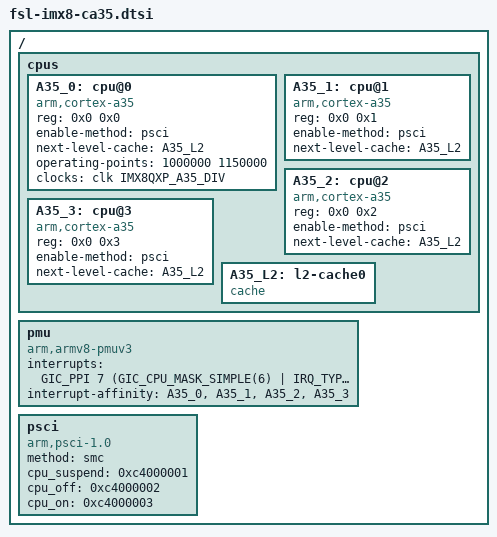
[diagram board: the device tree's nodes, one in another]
/*
 * Copyright (C) 2016 Freescale Semiconductor, Inc.
 * Copyright 2017 NXP
 *
 * This program is free software; you can redistribute it and/or
 * modify it under the terms of the GNU General Public License
 * as published by the Free Software Foundation; either version 2
 * of the License, or (at your option) any later version.
 *
 * This program is distributed in the hope that it will be useful,
 * but WITHOUT ANY WARRANTY; without even the implied warranty of
 * MERCHANTABILITY or FITNESS FOR A PARTICULAR PURPOSE.  See the
 * GNU General Public License for more details.
 */

#include <dt-bindings/clock/imx8qxp-clock.h>
#include <dt-bindings/interrupt-controller/arm-gic.h>

/{
	cpus {
		#address-cells = <2>;
		#size-cells = <0>;

		/* We have 1 clusters having 4 Cortex-A35 cores */
		A35_0: cpu@0 {
			device_type = "cpu";
			compatible = "arm,cortex-a35";
			reg = <0x0 0x0>;
			enable-method = "psci";
			next-level-cache = <&A35_L2>;
			operating-points = <
				/* kHz    uV */
				1000000 1150000
			>;
			clocks = <&clk IMX8QXP_A35_DIV>;
		};

		A35_1: cpu@1 {
			device_type = "cpu";
			compatible = "arm,cortex-a35";
			reg = <0x0 0x1>;
			enable-method = "psci";
			next-level-cache = <&A35_L2>;
		};

		A35_2: cpu@2 {
			device_type = "cpu";
			compatible = "arm,cortex-a35";
			reg = <0x0 0x2>;
			enable-method = "psci";
			next-level-cache = <&A35_L2>;
		};

		A35_3: cpu@3 {
			device_type = "cpu";
			compatible = "arm,cortex-a35";
			reg = <0x0 0x3>;
			enable-method = "psci";
			next-level-cache = <&A35_L2>;
		};

		A35_L2: l2-cache0 {
			compatible = "cache";
		};
	};

	pmu {
		compatible = "arm,armv8-pmuv3";
		interrupts = <GIC_PPI 7
			(GIC_CPU_MASK_SIMPLE(6) | IRQ_TYPE_LEVEL_HIGH)>;
		interrupt-affinity = <&A35_0>, <&A35_1>, <&A35_2>, <&A35_3>;
	};

	psci {
		compatible = "arm,psci-1.0";
		method = "smc";
		cpu_suspend   = <0xc4000001>;
		cpu_off	      = <0xc4000002>;
		cpu_on	      = <0xc4000003>;
	};
};
